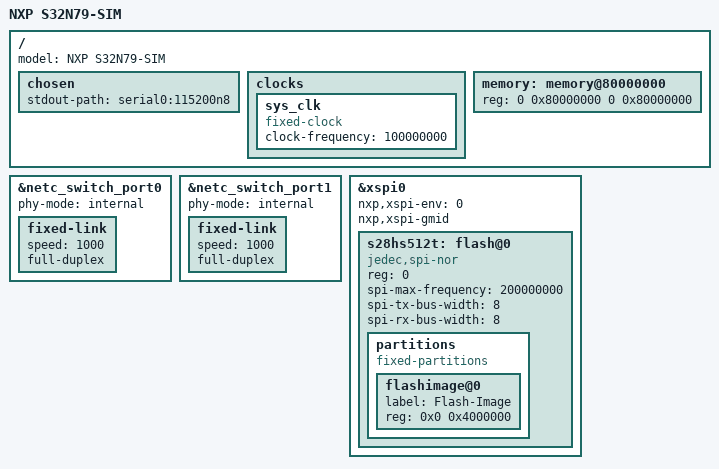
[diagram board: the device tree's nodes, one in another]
// SPDX-License-Identifier: (GPL-2.0+ OR BSD-3-Clause)
/*
 * Copyright 2024-2025 NXP
 */

/dts-v1/;
#include "s32n79.dtsi"

/ {
	model = "NXP S32N79-SIM";

	chosen {
		stdout-path = "serial0:115200n8";
	};

	clocks {
		sys_clk: sys_clk {
			compatible = "fixed-clock";
			clock-frequency = <100000000>;
			#clock-cells = <0>;
		};
	};

	memory: memory@80000000 {
		device_type = "memory";
		reg = <0 0x80000000 0 0x80000000>;
	};
};

&netc_switch_port0 {
	phy-mode = "internal";
	fixed-link {
		speed = <1000>;
		full-duplex;
	};
};

&netc_switch_port1 {
	phy-mode = "internal";
	fixed-link {
		speed = <1000>;
		full-duplex;
	};
};

&xspi0 {
	nxp,xspi-env = <0>;
	nxp,xspi-gmid;

	s28hs512t: flash@0 {
		compatible = "jedec,spi-nor";
		reg = <0>;
		spi-max-frequency = <200000000>;
		spi-tx-bus-width = <8>;
		spi-rx-bus-width = <8>;

		partitions {
			compatible = "fixed-partitions";
			#address-cells = <1>;
			#size-cells = <1>;

			/*
			 * By default, s28hs512t/s28hs01gt have a bottom hybrid
			 * configuration:
			 * - address range [0x0 - 0x1ffff] - 32 sectors
			 * of 4KB size
			 * - address range [0x20000 - 0x3ffff] - 1 sector of
			 * 128KB size
			 * - address range [0x3ffff - ...] - 256KB sectors
			 * The XSPI partitions should be defined taking into
			 * account the flash address space configuration.
			 */
			flashimage@0 {
				label = "Flash-Image";
				reg = <0x0 0x4000000>;
			};
		};
	};
};
